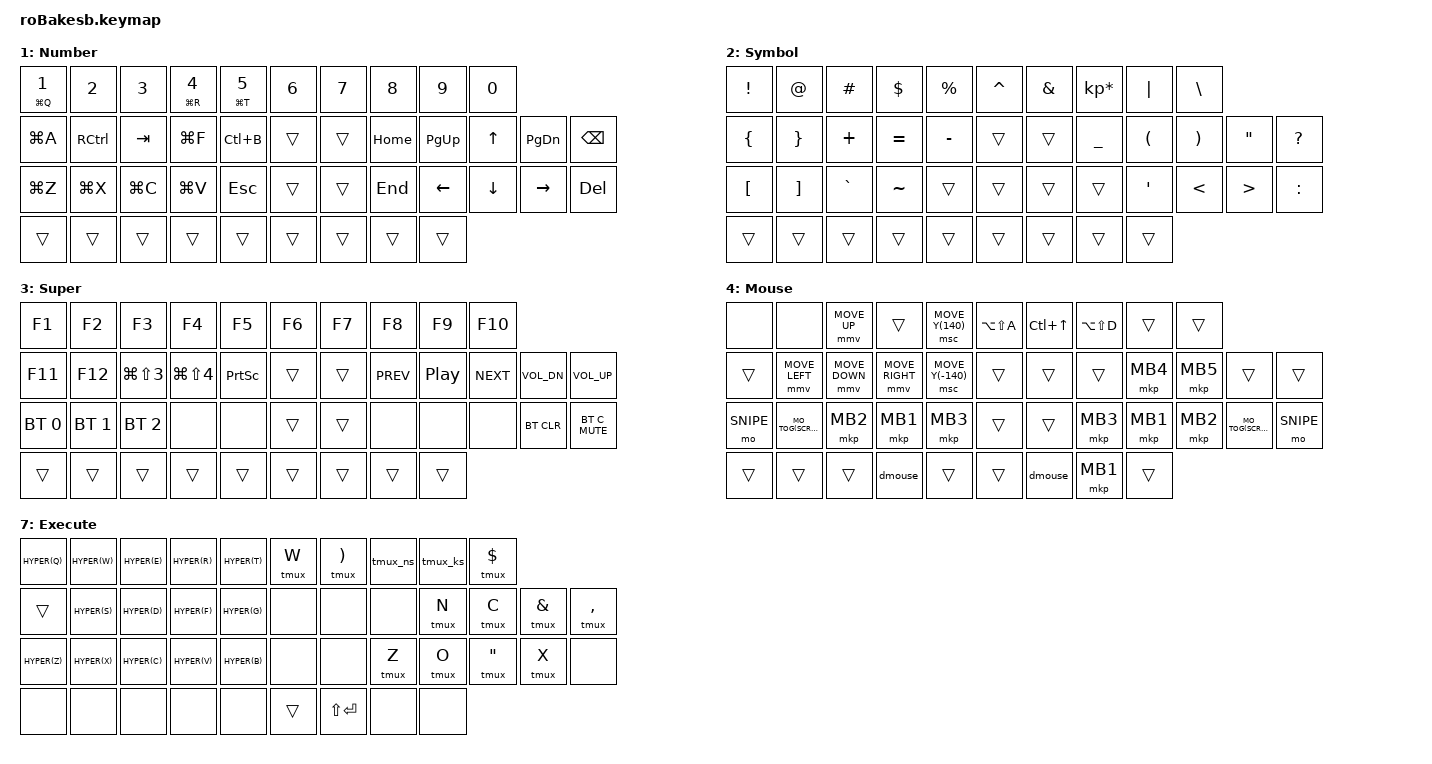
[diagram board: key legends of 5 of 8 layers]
#define ZMK_POINTING_DEFAULT_SCRL_VAL 200

#include <behaviors.dtsi>
#include <dt-bindings/zmk/keys.h>
#include <dt-bindings/zmk/bt.h>
#include <dt-bindings/zmk/ext_power.h>
#include <dt-bindings/zmk/mouse.h>
#include <dt-bindings/zmk/outputs.h>
#include <dt-bindings/zmk/pointing.h>
#include <behaviors/mouse_keys.dtsi>

#define MO_TOG(layer) &mo_tog layer layer   // Macro to apply momentary-layer-on-hold/toggle-layer-on-tap to a specific layer


#define DEFAU 0
#define NUMBE 1
#define SYMBO 2
#define SUPER 3
#define MOUSE 4
#define SCROL 5
#define SNIPE 6
#define EXECU 7

#define HYPER(key) LC(LA(LG(LS(key))))   // Ctrl+Option+Cmd+Shift: free shortcuts for Raycast

/ {
    cursor_move: cursor_move {
        compatible = "zmk,behavior-input-two-axis";
        #binding-cells= <1>;
        x-input-code = <INPUT_REL_HWHEEL>;
        y-input-code = <INPUT_REL_WHEEL>;
        time-to-max-speed-ms = <0>;
        acceleration-exponent = <0>;
    };
    mouse_wheel: mouse_wheel {
            compatible = "zmk,behavior-sensor-rotate";
            label = "MOUSE_WHEEL";
            #sensor-binding-cells = <0>;
            tap-ms = <20>;
            bindings = <&msc SCRL_UP>, <&msc SCRL_DOWN>;
    };
    rot_kp: sensor_rotate_kp {
            compatible = "zmk,behavior-sensor-rotate-var";
            #sensor-binding-cells = <2>;
            bindings = <&kp>, <&kp>;
    };
    conditional_layers {
        compatible = "zmk,conditional-layers";

        tri_layer {
            if-layers = <NUMBE SYMBO>;
            then-layer = <SUPER>;
        };
    };

    behaviors {
        hm: homerow_mods {
            compatible = "zmk,behavior-hold-tap";
            label = "HOMEROW_MODS";
            #binding-cells = <2>;
            tapping-term-ms = <200>;
            quick-tap-ms = <0>;
            flavor = "tap-preferred";
            bindings = <&kp>, <&kp>;
        };

        hk: homerow_hold {
            compatible = "zmk,behavior-hold-tap";
            label = "HOLD_MOD";
            #binding-cells = <2>;
            tapping-term-ms = <150>;
            quick-tap-ms = <0>;
            flavor = "hold-preferred";
            bindings = <&kp>, <&kp>;
        };

        hs: hold_custom {
            compatible = "zmk,behavior-hold-tap";
            label = "HOLD_CUSTOM";
            #binding-cells = <2>;
            tapping-term-ms = <500>;
            quick-tap-ms = <0>;
            flavor = "tap-preferred";
            bindings = <&kp>, <&kp>;
        };
        // Number layer: tap = digit, hold 400 ms = Cmd shortcut (longer than &hm so Cmd+Q needs intent)
        hn: hold_number {
            compatible = "zmk,behavior-hold-tap";
            label = "HOLD_NUMBER";
            #binding-cells = <2>;
            tapping-term-ms = <400>;
            quick-tap-ms = <0>;
            flavor = "tap-preferred";
            bindings = <&kp>, <&kp>;
        };

        // tap = key, hold = layer. require-prior-idle-ms: if another key was pressed in the last
        // 150 ms (mid-word), it resolves as tap right away, so typing never turns into the layer.
        hx: hold_layer {
            compatible = "zmk,behavior-hold-tap";
            label = "HOLD_LAYER";
            #binding-cells = <2>;
            tapping-term-ms = <200>;
            quick-tap-ms = <0>;
            require-prior-idle-ms = <150>;
            flavor = "tap-preferred";
            bindings = <&mo>, <&kp>;
        };

        mo_tog: behavior_mo_tog {
            compatible = "zmk,behavior-hold-tap";
            #binding-cells = <2>;
            flavor = "hold-preferred";
            tapping-term-ms = <200>;
            bindings = <&mo>, <&tog>;
        };
        swap: swapper {
            compatible = "zmk,behavior-tri-state";
            label = "SWAPPER";
            #binding-cells = <0>;
            bindings = <&kt LALT>, <&kp TAB>, <&kt LALT>;
            ignored-key-positions = <23>;
        };

        swapmac: swappermac {
            compatible = "zmk,behavior-tri-state";
            label = "SWAPPERMAC";
            #binding-cells = <0>;
            bindings = <&kt LGUI>, <&kp TAB>, <&kt LGUI>;
            ignored-key-positions = <22>;
        };
        w1: w1 {
            compatible = "zmk,behavior-tri-state";
            label = "WIN OPEN 1";
            #binding-cells = <0>;
            bindings = <&kt LGUI>, <&kp N1>, <&kt LGUI>;
        };

        w2: w2 {
            compatible = "zmk,behavior-tri-state";
            label = "WIN OPEN 2";
            #binding-cells = <0>;
            bindings = <&kt LGUI>, <&kp N2>, <&kt LGUI>;
        };

        w3: w3 {
            compatible = "zmk,behavior-tri-state";
            label = "WIN OPEN 3";
            #binding-cells = <0>;
            bindings = <&kt LGUI>, <&kp N3>, <&kt LGUI>;
        };

        w4: w4 {
            compatible = "zmk,behavior-tri-state";
            label = "WIN OPEN 4";
            #binding-cells = <0>;
            bindings = <&kt LGUI>, <&kp N4>, <&kt LGUI>;
        };

        w5: w5 {
            compatible = "zmk,behavior-tri-state";
            label = "WIN OPEN 5";
            #binding-cells = <0>;
            bindings = <&kt LGUI>, <&kp N5>, <&kt LGUI>;
        };

        w6: w6 {
            compatible = "zmk,behavior-tri-state";
            label = "WIN OPEN 6";
            #binding-cells = <0>;
            bindings = <&kt LGUI>, <&kp N6>, <&kt LGUI>;
        };

        w7: w7 {
            compatible = "zmk,behavior-tri-state";
            label = "WIN OPEN 7";
            #binding-cells = <0>;
            bindings = <&kt LGUI>, <&kp N7>, <&kt LGUI>;
        };

        w8: w8 {
            compatible = "zmk,behavior-tri-state";
            label = "WIN OPEN 8";
            #binding-cells = <0>;
            bindings = <&kt LGUI>, <&kp N8>, <&kt LGUI>;
        };

        w9: w9 {
            compatible = "zmk,behavior-tri-state";
            label = "WIN OPEN 9";
            #binding-cells = <0>;
            bindings = <&kt LGUI>, <&kp N9>, <&kt LGUI>;
        };
    };

    macros {

        dmouse: dmouse {
            label = "deactivate_mouse";
            compatible = "zmk,behavior-macro";
            #binding-cells = <0>;
            wait-ms = <0>;
            tap-ms = <0>;
            bindings = <&mo MOUSE>, <&mo SCROL>,  <&mo SNIPE>;
        };

        // tmux: Ctrl+B then the given key (&tmux W = prefix, w)
        tmux: tmux_prefix {
            compatible = "zmk,behavior-macro-one-param";
            #binding-cells = <1>;
            bindings = <&kp LC(B)>, <&macro_param_1to1>, <&kp MACRO_PLACEHOLDER>;
        };

        // tmux: new session via the command prompt (no default key for it)
        tmux_ns: tmux_new_session {
            compatible = "zmk,behavior-macro";
            #binding-cells = <0>;
            bindings = <&kp LC(B)>, <&kp COLON &kp N &kp E &kp W &kp MINUS &kp S &kp E &kp S &kp S &kp I &kp O &kp N &kp RET>;
        };

        // tmux: stay in tmux after killing the session, and ask y/n first
        tmux_ks: tmux_kill_session {
            compatible = "zmk,behavior-macro";
            #binding-cells = <0>;
            bindings = <&kp LC(B)>, <&kp COLON &kp S &kp E &kp T &kp SPACE &kp MINUS &kp G &kp SPACE &kp D &kp E &kp T &kp A &kp C &kp H &kp MINUS &kp O &kp N &kp MINUS &kp D &kp E &kp S &kp T &kp R &kp O &kp Y &kp SPACE &kp O &kp F &kp F &kp SPACE &kp SEMI &kp SPACE &kp C &kp O &kp N &kp F &kp I &kp R &kp M &kp MINUS &kp B &kp E &kp F &kp O &kp R &kp E &kp SPACE &kp K &kp I &kp L &kp L &kp MINUS &kp S &kp E &kp S &kp S &kp I &kp O &kp N &kp RET>;
        };

    };

    keymap {
        compatible = "zmk,keymap";

        default_layer {
            label = "Mac";
            bindings = <
 &kp Q                &kp W                &kp E                &kp R                &kp T                &kp Y                &kp U                &kp I                &kp O                &kp P               
 &hx EXECU A          &hm LCTRL S          &hm LALT D           &hm LGUI F           &kp G                &kp LG(LC(LS(N4)))   &none                &kp H                &hm LGUI J           &hm RALT K           &hm RCTRL L          &kp FSLH             
 &kp Z                &kp X                &kp C                &kp V                &kp B                &kp TAB                &none                &kp N                &kp M                &kp COMMA            &kp DOT              &kp SEMI             
 &none                &trans               &none                &mo MOUSE            &mo NUMBE            &hm LSHFT SPACE      &hk RSHFT RET        &mo SYMBO            &none 
            >;

            sensor-bindings = <&mouse_wheel>;
        };

lower_layer {
            label = "Number";
            bindings = <
 &hn LG(Q) N1         &kp N2               &kp N3               &hn LG(R) N4         &hn LG(T) N5         &kp N6               &kp N7               &kp N8               &kp N9               &kp N0               
 &kp LG(A)            &kp RCTRL            &kp TAB              &kp LG(F)            &kp LC(B)            &trans               &trans               &kp HOME             &kp PG_UP            &kp UP               &kp PG_DN            &kp BSPC 
 &kp LG(Z)            &kp LG(X)            &kp LG(C)            &kp LG(V)            &kp ESC              &trans               &trans               &kp END              &kp LEFT             &kp DOWN             &kp RIGHT            &kp DEL 
 &trans               &trans               &trans               &trans               &trans               &trans               &trans               &trans               &trans 
            >;

            sensor-bindings = <&rot_kp C_VOL_UP C_VOL_DN>;
        };

raise_layer {
            label = "Symbol";
            bindings = <
 &kp EXCL              &kp AT                &kp HASH             &kp DLLR             &kp PRCNT            &kp CARET            &kp AMPS             &kp KP_MULTIPLY     &kp PIPE            &kp BSLH             
 &kp LBRC             &kp RBRC             &kp PLUS             &kp EQUAL            &kp MINUS            &trans               &trans               &kp UNDER            &kp LPAR            &kp RPAR            &kp DQT             &kp QMARK           
 &kp LBKT             &kp RBKT             &kp GRAVE            &kp TILDE           &trans               &trans               &trans               &trans              &kp SQT             &kp LT              &kp GT             &kp COLON           
 &trans               &trans               &trans               &trans               &trans               &trans               &trans               &trans               &trans               
            >;
            sensor-bindings = <&rot_kp C_VOL_UP C_VOL_DN>;
        };

        super_layer {
            label = "Super";
            bindings = <
 &kp F1                &kp F2                &kp F3                &kp F4                &kp F5                &kp F6                &kp F7                &kp F8                &kp F9               &kp F10               
 &kp F11               &kp F12              &kp LG(LS(N3))       &kp LG(LS(N4))       &kp PSCRN            &trans               &trans               &kp C_PREV            &kp C_PP              &kp C_NEXT           &kp C_VOL_DN         &kp C_VOL_UP         
 &bt BT_SEL 0          &bt BT_SEL 1          &bt BT_SEL 2          &none                 &none                 &trans               &trans               &none                &none                &none                &bt BT_CLR           &bt C_MUTE          
 &trans               &trans               &trans               &trans               &trans               &trans               &trans               &trans               &trans               
            >;
        };

        mouse_layer {
            label = "Mouse";
            bindings = <
 &none                 &none                 &mmv MOVE_UP          &trans               &msc MOVE_Y(140)      &kp LA(LS(A))        &kp LC(UP)           &kp LA(LS(D))        &trans               &trans               
 &trans               &mmv MOVE_LEFT       &mmv MOVE_DOWN      &mmv MOVE_RIGHT     &msc MOVE_Y(-140)    &trans               &trans               &trans               &mkp MB4             &mkp MB5             &trans               &trans              
 &mo SNIPE            MO_TOG(SCROL)       &mkp MB2             &mkp MB1             &mkp MB3             &trans               &trans               &mkp MB3             &mkp MB1             &mkp MB2           MO_TOG(SCROL)       &mo SNIPE           
 &trans               &trans               &trans               &dmouse             &trans               &trans               &dmouse             &mkp MB1            &trans              
            >;
        };


scroll {
            label = "Scroll";
            bindings = <
 &trans               &trans               &trans               &trans               &trans               &trans               &trans               &trans               &trans               &trans               
 &trans               &trans               &trans               &trans               &trans               &trans               &trans               &trans               &trans               &trans               
 &trans               &trans               &trans               &trans               &trans               &trans               &trans               &trans               &trans               &trans               
 &trans               &trans               &trans               &trans               &trans               &trans               &trans               &trans               &trans               
            >;
        };

snipe {
            label = "Snipe";
            bindings = <
 &trans               &trans               &trans               &trans               &trans               &trans               &trans               &trans               &trans               &trans               
 &trans               &trans               &trans               &trans               &trans               &trans               &trans               &trans               &trans               &trans               
 &trans               &trans               &trans               &trans               &trans               &trans               &trans               &trans               &trans               &trans               
 &trans               &trans               &trans               &trans               &trans               &trans               &trans               &trans               &trans               
            >;
        };

        execute_layer {
            label = "Execute";
            bindings = <
 &kp HYPER(Q)         &kp HYPER(W)         &kp HYPER(E)         &kp HYPER(R)         &kp HYPER(T)         &tmux W              &tmux RPAR           &tmux_ns             &tmux_ks             &tmux DLLR           
 &trans               &kp HYPER(S)         &kp HYPER(D)         &kp HYPER(F)         &kp HYPER(G)         &none                &none                &none                &tmux N              &tmux C              &tmux AMPS           &tmux COMMA          
 &kp HYPER(Z)         &kp HYPER(X)         &kp HYPER(C)         &kp HYPER(V)         &kp HYPER(B)         &none                &none                &tmux Z              &tmux O              &tmux DQT            &tmux X              &none                
 &none                &none                &none                &none                &none                &trans               &kp LS(RET)          &none                &none                
            >;
        };
    };
};
